# M475 register map
File version: 2.0.2.5
Registers are 32-bit, read-write, reset 0x0 unless marked. A register's access mark holds for its fields unless they carry their own. Offsets are from the block's base; [hi:lo] are bit positions; {n}, {i} and the like mark numbered series.

## PE — Port E
Base 0x400C0400
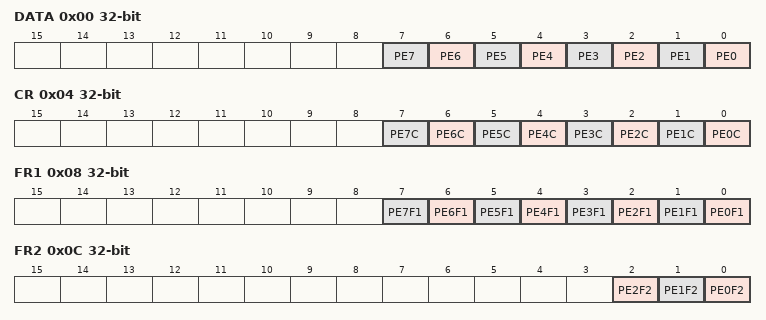
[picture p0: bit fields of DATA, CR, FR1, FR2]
0x00 DATA — Port E Data Register
  [n] PE{n} (n=0..7)
0x04 CR — Port E Output Control Register
  [n] PE{n}C (n=0..7)
0x08 FR1 — Port E Function Register 1
  [n] PE{n}F1 (n=0..7)
0x0C FR2 — Port E Function Register 2
  [2] PE2F2, [1] PE1F2, [0] PE0F2
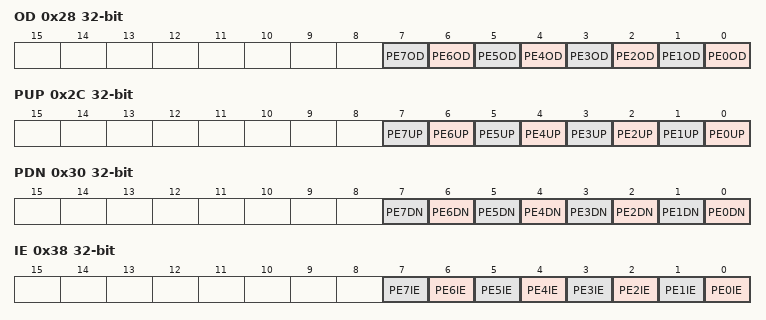
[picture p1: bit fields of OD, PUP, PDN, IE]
0x28 OD — Port E Open Drain Control Register
  [n] PE{n}OD (n=0..7)
0x2C PUP — Port E Pull-up Control Register
  [n] PE{n}UP (n=0..7)
0x30 PDN — Port E Pull-down Control Register
  [n] PE{n}DN (n=0..7)
0x38 IE — Port E Input Control Register
  [n] PE{n}IE (n=0..7)

## PF — Port F
Base 0x400C0500
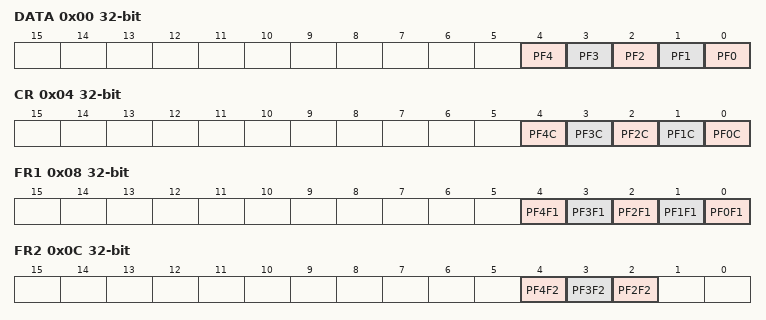
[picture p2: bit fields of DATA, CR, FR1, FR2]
0x00 DATA — Port F Data Register
  [n] PF{n} (n=0..4)
0x04 CR — Port F Output Control Register
  [n] PF{n}C (n=0..4)
0x08 FR1 — Port F Function Register 1
  [n] PF{n}F1 (n=0..4)
0x0C FR2 — Port F Function Register 2
  [4] PF4F2, [3] PF3F2, [2] PF2F2
0x10 FR3 — Port F Function Register 3
  [2] PF2F3
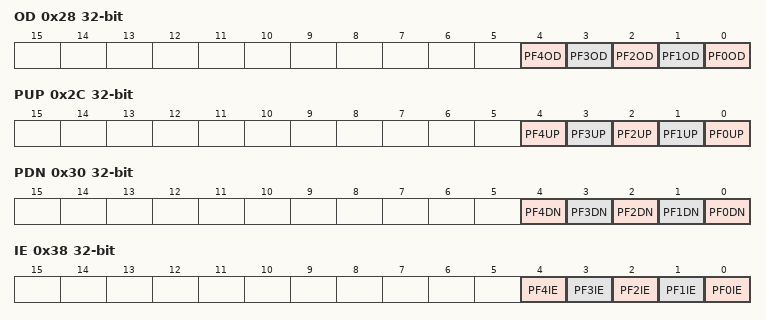
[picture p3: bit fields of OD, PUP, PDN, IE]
0x28 OD — Port F Open Drain Control Register
  [n] PF{n}OD (n=0..4)
0x2C PUP — Port F Pull-up Control Register
  [n] PF{n}UP (n=0..4)
0x30 PDN — Port F Pull-down Control Register
  [n] PF{n}DN (n=0..4)
0x38 IE — Port F Input Control Register
  [n] PF{n}IE (n=0..4)

## PG — Port G
Base 0x400C0600
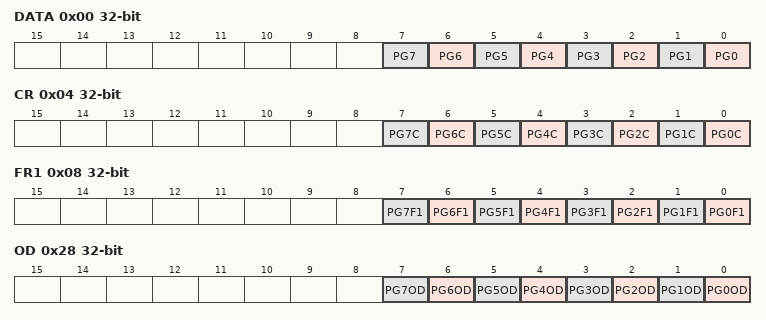
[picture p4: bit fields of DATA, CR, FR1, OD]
0x00 DATA — Port G Data Register
  [n] PG{n} (n=0..7)
0x04 CR — Port G Output Control Register
  [n] PG{n}C (n=0..7)
0x08 FR1 — Port G Function Register 1
  [n] PG{n}F1 (n=0..7)
0x28 OD — Port G Open Drain Control Register
  [n] PG{n}OD (n=0..7)
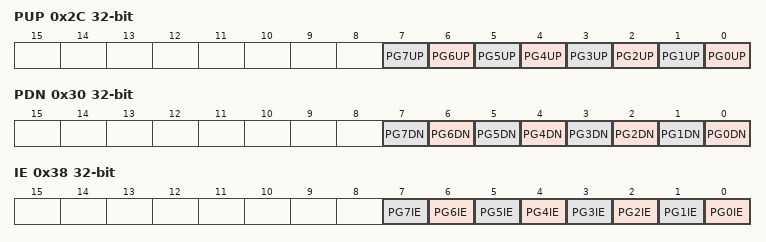
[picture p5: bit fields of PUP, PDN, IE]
0x2C PUP — Port G Pull-up Control Register
  [n] PG{n}UP (n=0..7)
0x30 PDN — Port G Pull-down Control Register
  [n] PG{n}DN (n=0..7)
0x38 IE — Port G Input Control Register
  [n] PG{n}IE (n=0..7)

## PH — Port H
Base 0x400C0700
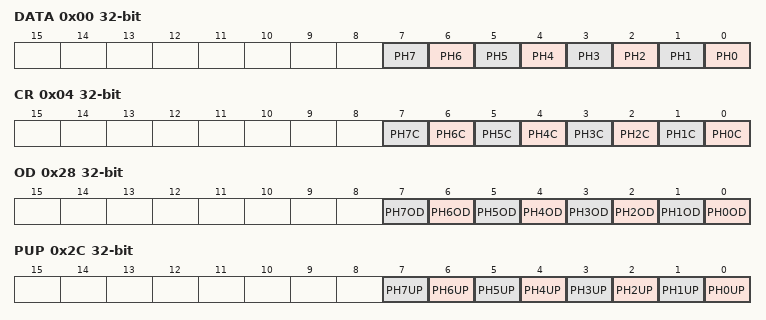
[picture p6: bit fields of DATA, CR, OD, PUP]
0x00 DATA — Port H Data Register
  [n] PH{n} (n=0..7)
0x04 CR — Port H Output Control Register
  [n] PH{n}C (n=0..7)
0x28 OD — Port H Open Drain Control Register
  [n] PH{n}OD (n=0..7)
0x2C PUP — Port H Pull-up Control Register
  [n] PH{n}UP (n=0..7)
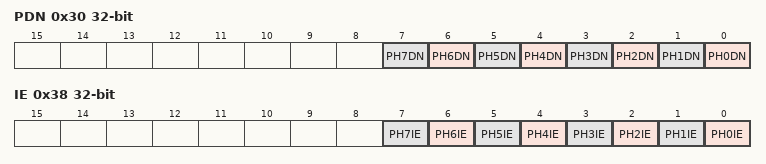
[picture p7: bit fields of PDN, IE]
0x30 PDN — Port H Pull-down Control Register
  [n] PH{n}DN (n=0..7)
0x38 IE — Port H Input Control Register
  [n] PH{n}IE (n=0..7)

## PJ — Port J
Base 0x400C0800
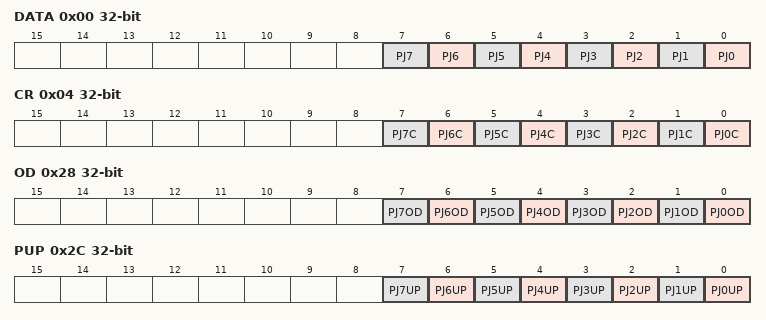
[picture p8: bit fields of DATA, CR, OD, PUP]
0x00 DATA — Port J Data Register
  [n] PJ{n} (n=0..7)
0x04 CR — Port J Output Control Register
  [n] PJ{n}C (n=0..7)
0x28 OD — Port J Open Drain Control Register
  [n] PJ{n}OD (n=0..7)
0x2C PUP — Port J Pull-up Control Register
  [n] PJ{n}UP (n=0..7)
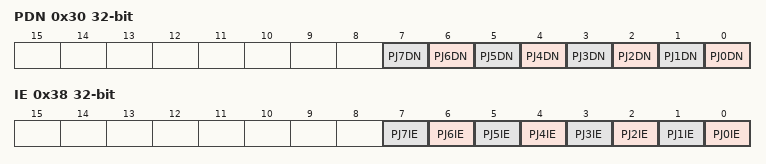
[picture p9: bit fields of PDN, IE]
0x30 PDN — Port J Pull-down Control Register
  [n] PJ{n}DN (n=0..7)
0x38 IE — Port J Input Control Register
  [n] PJ{n}IE (n=0..7)

## PK — Port K
Base 0x400C0900
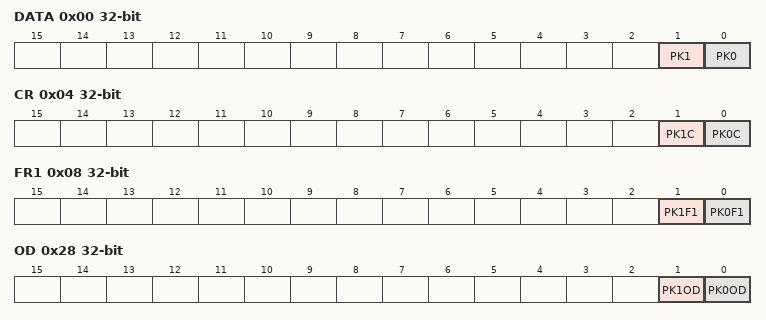
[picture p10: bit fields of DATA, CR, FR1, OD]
0x00 DATA — Port K Data Register
  [1] PK1, [0] PK0
0x04 CR — Port K Output Control Register
  [1] PK1C, [0] PK0C
0x08 FR1 — Port K Function Register 1
  [1] PK1F1, [0] PK0F1
0x28 OD — Port K Open Drain Control Register
  [1] PK1OD, [0] PK0OD
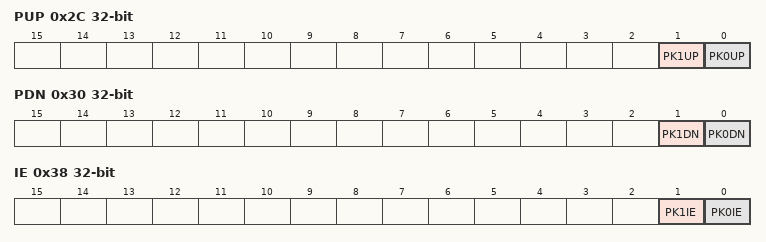
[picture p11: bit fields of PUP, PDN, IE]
0x2C PUP — Port K Pull-up Control Register
  [1] PK1UP, [0] PK0UP
0x30 PDN — Port K Pull-down Control Register
  [1] PK1DN, [0] PK0DN
0x38 IE — Port K Input Control Register
  [1] PK1IE, [0] PK0IE

## PL — Port L
Base 0x400C0A00
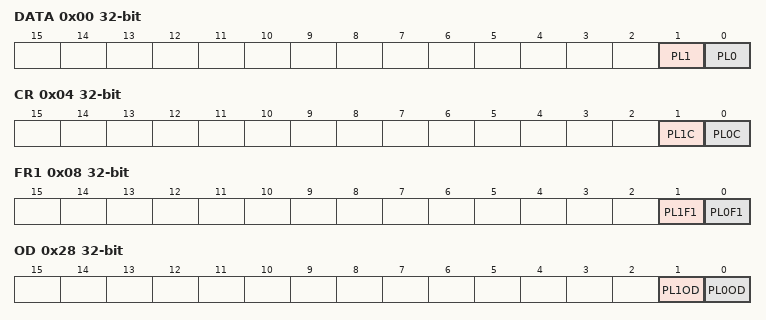
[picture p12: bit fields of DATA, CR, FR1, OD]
0x00 DATA — Port L Data Register
  [1] PL1, [0] PL0
0x04 CR — Port L Output Control Register
  [1] PL1C, [0] PL0C
0x08 FR1 — Port L Function Register 1
  [1] PL1F1, [0] PL0F1
0x28 OD — Port L Open Drain Control Register
  [1] PL1OD, [0] PL0OD
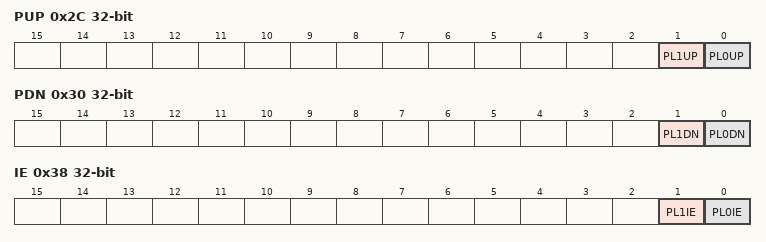
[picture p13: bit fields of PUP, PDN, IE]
0x2C PUP — Port L Pull-up Control Register
  [1] PL1UP, [0] PL0UP
0x30 PDN — Port L Pull-down Control Register
  [1] PL1DN, [0] PL0DN
0x38 IE — Port L Input Control Register
  [1] PL1IE, [0] PL0IE

## PN — Port N
Base 0x400C0C00
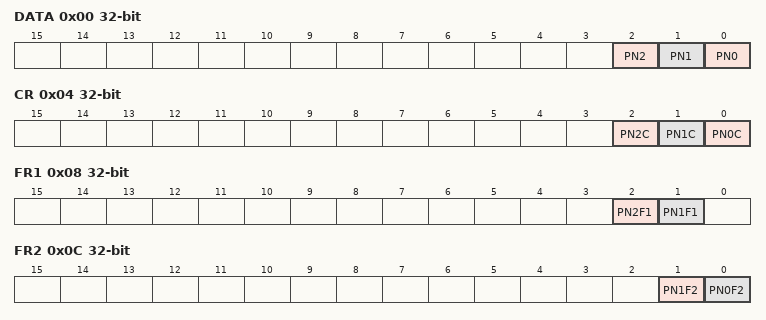
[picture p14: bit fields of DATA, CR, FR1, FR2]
0x00 DATA — Port N Data Register
  [2] PN2, [1] PN1, [0] PN0
0x04 CR — Port N Output Control Register
  [2] PN2C, [1] PN1C, [0] PN0C
0x08 FR1 — Port N Function Register 1
  [2] PN2F1, [1] PN1F1
0x0C FR2 — Port N Function Register 2
  [1] PN1F2, [0] PN0F2
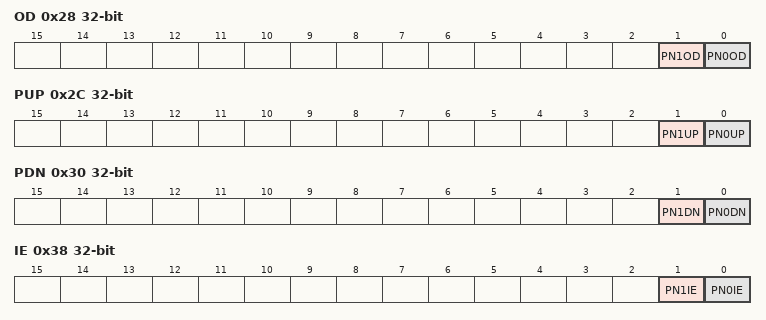
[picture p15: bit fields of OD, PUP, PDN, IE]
0x28 OD — Port N Open Drain Register
  [1] PN1OD, [0] PN0OD
0x2C PUP — Port N Pull-up Control Register
  [1] PN1UP, [0] PN0UP
0x30 PDN — Port N Pull-down Control Register
  [1] PN1DN, [0] PN0DN
0x38 IE — Port N Input Control Register
  [1] PN1IE, [0] PN0IE
